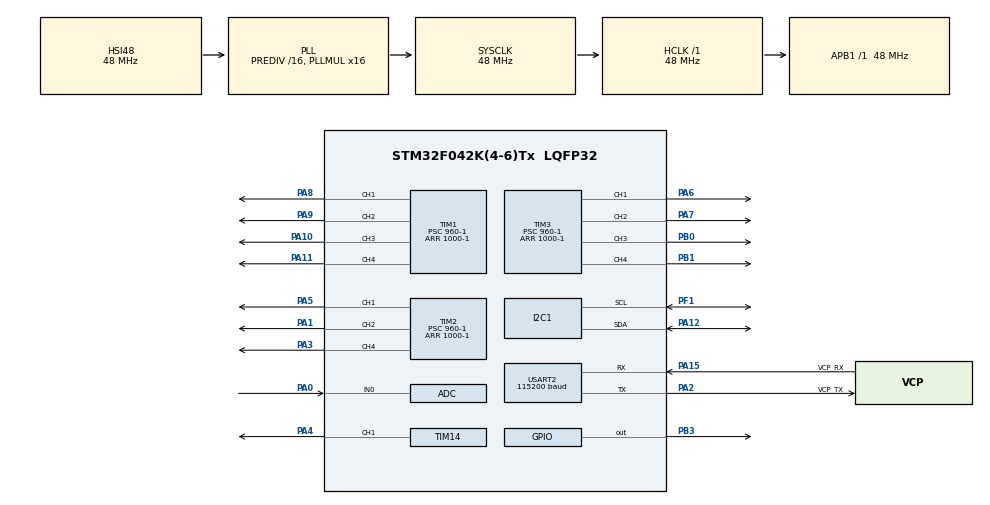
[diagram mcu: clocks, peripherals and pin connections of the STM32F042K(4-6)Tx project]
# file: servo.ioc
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ADC.ContinuousConvMode=ENABLE
Dma.Request0=TIM16_CH1/UP
Dma.TIM16_CH1/UP.0.Direction=DMA_PERIPH_TO_MEMORY
Dma.TIM16_CH1/UP.0.Instance=DMA1_Channel3
Dma.TIM16_CH1/UP.0.MemDataAlignment=DMA_MDATAALIGN_BYTE
Dma.TIM16_CH1/UP.0.MemInc=DMA_MINC_ENABLE
Dma.TIM16_CH1/UP.0.Mode=DMA_NORMAL
Dma.TIM16_CH1/UP.0.PeriphDataAlignment=DMA_PDATAALIGN_BYTE
Dma.TIM16_CH1/UP.0.PeriphInc=DMA_PINC_DISABLE
Dma.TIM16_CH1/UP.0.Priority=DMA_PRIORITY_LOW
Mcu.Family=STM32F0
Mcu.Name=STM32F042K(4-6)Tx
Mcu.Package=LQFP32
NVIC.DMA1_Channel2_3_IRQn=true\:0\:0\:false\:false\:true\:false\:true
NVIC.USART2_IRQn=true\:0\:0\:false\:false\:true\:true\:true
PA0.Mode=IN0
PA0.Signal=ADC_IN0
PA1.Signal=S_TIM2_CH2
PA10.Signal=S_TIM1_CH3
PA11.Signal=S_TIM1_CH4
PA12.Mode=I2C
PA12.Signal=I2C1_SDA
PA13.GPIO_Label=SWDIO
PA13.Mode=Serial_Wire
PA13.Signal=SYS_SWDIO
PA14.GPIO_Label=SWCLK
PA14.Mode=Serial_Wire
PA14.Signal=SYS_SWCLK
PA15.GPIO_Label=VCP_RX
PA15.Mode=Asynchronous
PA15.Signal=USART2_RX
PA2.GPIO_Label=VCP_TX
PA2.Mode=Asynchronous
PA2.Signal=USART2_TX
PA3.Signal=S_TIM2_CH4
PA4.Signal=S_TIM14_CH1
PA5.Signal=S_TIM2_CH1_ETR
PA6.Signal=S_TIM3_CH1
PA7.Signal=S_TIM3_CH2
PA8.Signal=S_TIM1_CH1
PA9.Signal=S_TIM1_CH2
PB0.Signal=S_TIM3_CH3
PB1.Signal=S_TIM3_CH4
PB3.Signal=GPIO_Output
PF0-OSC_IN.GPIO_Label=MCO
PF0-OSC_IN.Mode=HSE-External-Clock-Source
PF0-OSC_IN.Signal=RCC_OSC_IN
PF1-OSC_OUT.Mode=I2C
PF1-OSC_OUT.Signal=I2C1_SCL
ProjectManager.HeapSize=0x200
ProjectManager.StackSize=0x600
ProjectManager.TargetToolchain=MDK-ARM V5.32
RCC.AHBFreq_Value=48000000
RCC.APB1Freq_Value=48000000
RCC.APB1TimFreq_Value=48000000
RCC.HCLKFreq_Value=48000000
RCC.PLLDivider=RCC_PREDIV_DIV16
RCC.PLLMUL=RCC_PLL_MUL16
RCC.PLLSourceVirtual=RCC_PLLSOURCE_HSI48
RCC.SYSCLKFreq_VALUE=48000000
RCC.SYSCLKSource=RCC_SYSCLKSOURCE_PLLCLK
SH.S_TIM14_CH1.0=TIM14_CH1,PWM Generation1 CH1
SH.S_TIM1_CH1.0=TIM1_CH1,PWM Generation1 CH1
SH.S_TIM1_CH2.0=TIM1_CH2,PWM Generation2 CH2
SH.S_TIM1_CH3.0=TIM1_CH3,PWM Generation3 CH3
SH.S_TIM1_CH4.0=TIM1_CH4,PWM Generation4 CH4
SH.S_TIM2_CH1_ETR.0=TIM2_CH1,PWM Generation1 CH1
SH.S_TIM2_CH2.0=TIM2_CH2,PWM Generation2 CH2
SH.S_TIM2_CH4.0=TIM2_CH4,PWM Generation4 CH4
SH.S_TIM3_CH1.0=TIM3_CH1,PWM Generation1 CH1
SH.S_TIM3_CH2.0=TIM3_CH2,PWM Generation2 CH2
SH.S_TIM3_CH3.0=TIM3_CH3,PWM Generation3 CH3
SH.S_TIM3_CH4.0=TIM3_CH4,PWM Generation4 CH4
TIM1.Channel-PWM\ Generation1\ CH1=TIM_CHANNEL_1
TIM1.Channel-PWM\ Generation2\ CH2=TIM_CHANNEL_2
TIM1.Channel-PWM\ Generation3\ CH3=TIM_CHANNEL_3
TIM1.Channel-PWM\ Generation4\ CH4=TIM_CHANNEL_4
TIM1.Period=1000-1
TIM1.Prescaler=960-1
TIM14.Channel=TIM_CHANNEL_1
TIM14.Period=1000-1
TIM14.Prescaler=960-1
TIM16.Period=1000-1
TIM16.Prescaler=960-1
TIM17.Period=1000-1
TIM17.Prescaler=960-1
TIM2.Channel-PWM\ Generation1\ CH1=TIM_CHANNEL_1
TIM2.Channel-PWM\ Generation2\ CH2=TIM_CHANNEL_2
TIM2.Channel-PWM\ Generation4\ CH4=TIM_CHANNEL_4
TIM2.Period=1000-1
TIM2.Prescaler=960-1
TIM3.Channel-PWM\ Generation1\ CH1=TIM_CHANNEL_1
TIM3.Channel-PWM\ Generation2\ CH2=TIM_CHANNEL_2
TIM3.Channel-PWM\ Generation3\ CH3=TIM_CHANNEL_3
TIM3.Channel-PWM\ Generation4\ CH4=TIM_CHANNEL_4
TIM3.Period=1000-1
TIM3.Prescaler=960-1
USART2.BaudRate=115200
USART2.VirtualMode-Asynchronous=VM_ASYNC
VP_TIM14_VS_ClockSourceINT.Mode=Enable_Timer
VP_TIM16_VS_ClockSourceINT.Mode=Enable_Timer
VP_TIM17_VS_ClockSourceINT.Mode=Enable_Timer
board=NUCLEO-F042K6

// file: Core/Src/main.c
/* USER CODE BEGIN Header */
/**
  ******************************************************************************
  * @file           : main.c
  * @brief          : Main program body
  ******************************************************************************
  * @attention
  *
  * Copyright (c) 2022 STMicroelectronics.
  * All rights reserved.
  *
  * This software is licensed under terms that can be found in the LICENSE file
  * in the root directory of this software component.
  * If no LICENSE file comes with this software, it is provided AS-IS.
  *
  ******************************************************************************
  */
/* USER CODE END Header */
#include "main.h"
#include "adc.h"
#include "dma.h"
#include "i2c.h"
#include "tim.h"
#include "usart.h"
#include "gpio.h"

/* USER CODE BEGIN Includes */
#include <stdio.h> //printf function
#include <string.h>
#include <stdbool.h>
#include "servo.h"
/* USER CODE END Includes */

void SystemClock_Config(void);

/* USER CODE BEGIN 0 */
ServoTypeDef servo[12];
/* USER CODE END 0 */

int main(void)
{

  /* MCU Configuration--------------------------------------------------------*/

  /* Reset of all peripherals, Initializes the Flash interface and the Systick. */
  HAL_Init();

  /* Configure the system clock */
  SystemClock_Config();

  /* Initialize all configured peripherals */
  MX_GPIO_Init();
  MX_TIM2_Init();
  MX_TIM3_Init();
  MX_TIM14_Init();
  MX_TIM16_Init();
  MX_TIM17_Init();
  MX_USART2_UART_Init();
  MX_I2C1_Init();
  MX_ADC_Init();
  MX_DMA_Init();
  MX_TIM1_Init();
  /* USER CODE BEGIN 2 */

	/* Servo Motors Configuration--------------------------------------------------------*/
	servos_init(servo);

  /* USER CODE END 2 */

  /* Infinite loop */
  /* USER CODE BEGIN WHILE */

//arm_set(25,25,25,25,25);
//arm_set(125,125,125,125,125);
//arm_set(25,25,25,25,25);
//arm_set(125,125,125,125,125);
//arm_set(25,50,75,100,125);
//arm_set(125,25,50,75,100);
//arm_set(25,50,75,100,125);
//arm_set(125,25,50,75,100);
//arm_set(75,75,75,75,75);
//arm_set(25,25,25,25,25);

//	arm_set(25,25,25,25,25);
//	arm_set(25,75,25,25,25);
//	arm_set(25,75,125,25,25);
//	arm_set(25,125,25,25,25);
//	arm_set(25,125,25,125,25);

//arm_set(NULL,25,NULL,NULL,NULL);
//arm_set(NULL,125,NULL,NULL,NULL);
//arm_set(NULL,25,NULL,NULL,NULL);
//arm_set(NULL,125,NULL,NULL,NULL);
//arm_set(NULL,25,NULL,NULL,NULL);

//arm_set(NULL,25,NULL,NULL,NULL);
//HAL_Delay(3000);
//arm_set(NULL,125,NULL,NULL,NULL);
//arm_set(NULL,75,NULL,NULL,NULL);

//arm_set(NULL,NULL,NULL,NULL,27);
//arm_set(NULL,NULL,NULL,NULL,82);
//arm_set(NULL,NULL,NULL,NULL,45);
//arm_set(NULL,NULL,NULL,NULL,82);
//arm_set(NULL,NULL,NULL,NULL,45);

uint32_t stable_time = HAL_GetTick();
//all_pwm_stop();

  while (1)
  {
    /* USER CODE END WHILE */
		if(HAL_GetTick()-stable_time>=50){
			arm_pwm_stop();
		}
		if(HAL_GetTick()-stable_time>=200){
			stable_time=HAL_GetTick();
			arm_pwm_return();
		}
    /* USER CODE BEGIN 3 */
//		printf("test\\n\n");
//		printf("test\\n\\r\n\r");

  }

  /* USER CODE END 3 */
}

void SystemClock_Config(void)
{
  RCC_OscInitTypeDef RCC_OscInitStruct = {0};
  RCC_ClkInitTypeDef RCC_ClkInitStruct = {0};
  RCC_PeriphCLKInitTypeDef PeriphClkInit = {0};

  /** Initializes the RCC Oscillators according to the specified parameters
  * in the RCC_OscInitTypeDef structure.
  */
  RCC_OscInitStruct.OscillatorType = RCC_OSCILLATORTYPE_HSI|RCC_OSCILLATORTYPE_HSI14
                              |RCC_OSCILLATORTYPE_HSI48;
  RCC_OscInitStruct.HSIState = RCC_HSI_ON;
  RCC_OscInitStruct.HSI48State = RCC_HSI48_ON;
  RCC_OscInitStruct.HSI14State = RCC_HSI14_ON;
  RCC_OscInitStruct.HSICalibrationValue = RCC_HSICALIBRATION_DEFAULT;
  RCC_OscInitStruct.HSI14CalibrationValue = 16;
  RCC_OscInitStruct.PLL.PLLState = RCC_PLL_ON;
  RCC_OscInitStruct.PLL.PLLSource = RCC_PLLSOURCE_HSI48;
  RCC_OscInitStruct.PLL.PLLMUL = RCC_PLL_MUL16;
  RCC_OscInitStruct.PLL.PREDIV = RCC_PREDIV_DIV16;
  if (HAL_RCC_OscConfig(&RCC_OscInitStruct) != HAL_OK)
  {
    Error_Handler();
  }
  /** Initializes the CPU, AHB and APB buses clocks
  */
  RCC_ClkInitStruct.ClockType = RCC_CLOCKTYPE_HCLK|RCC_CLOCKTYPE_SYSCLK
                              |RCC_CLOCKTYPE_PCLK1;
  RCC_ClkInitStruct.SYSCLKSource = RCC_SYSCLKSOURCE_PLLCLK;
  RCC_ClkInitStruct.AHBCLKDivider = RCC_SYSCLK_DIV1;
  RCC_ClkInitStruct.APB1CLKDivider = RCC_HCLK_DIV1;

  if (HAL_RCC_ClockConfig(&RCC_ClkInitStruct, FLASH_LATENCY_1) != HAL_OK)
  {
    Error_Handler();
  }
  PeriphClkInit.PeriphClockSelection = RCC_PERIPHCLK_I2C1;
  PeriphClkInit.I2c1ClockSelection = RCC_I2C1CLKSOURCE_HSI;
  if (HAL_RCCEx_PeriphCLKConfig(&PeriphClkInit) != HAL_OK)
  {
    Error_Handler();
  }
}

void Error_Handler(void)
{
  __disable_irq();
  while (1)
  {
  }
}
